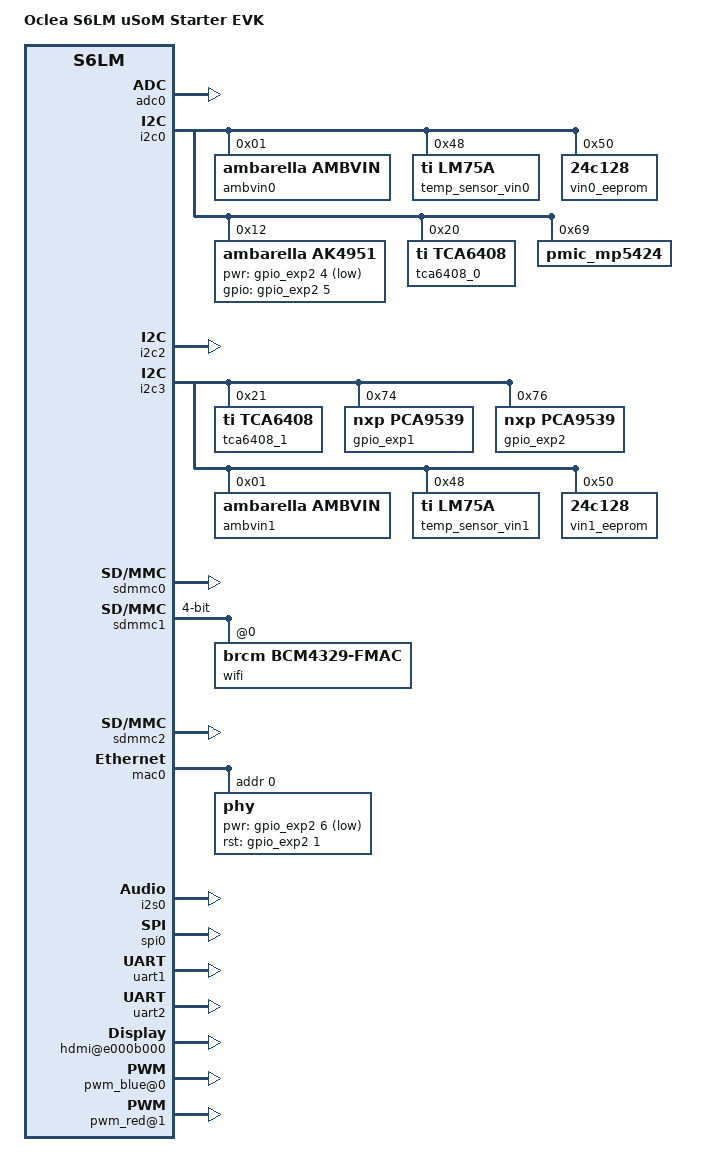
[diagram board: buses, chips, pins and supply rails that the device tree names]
/dts-v1/;
/include/ "ambarella-s6lm.dtsi"
/ {
 reserved-memory {
  #address-cells = <1>;
  #size-cells = <1>;
  ranges;
  linux,cma {
   compatible = "shared-dma-pool";
   reusable;
   size = <0x02000000>;
   linux,cma-default;
  };
  iav_reserved: iav@0x1a800000 {
   compatible = "shared-dma-pool";
   reusable;
   reg = <0x1a800000 (0x40000000 - 0x1a800000 - 0x400000)>;
  };
 };
 iav {
  ambcma {
   compatible = "ambarella,cma";
   memory-region = <&iav_reserved>;
  };
 };
};
/ {
 iav {
  hwtimer {
   compatible = "ambarella,hwtimer";
   interrupts = <0 25 0x1>;
   interrupt-names = "hwtimer";
  };
 };
 clocks {
  pll_out_hdmi: pll_out_hdmi {
   assigned-clock-rates = <270000000>;
  };
  gclk_so: gclk-so {
   assigned-clock-rates = <37125000>;
  };
 };
};
/ {
 som_type = "Oclea S6LM uSoM";
 model = "Oclea S6LM uSoM Starter EVK";
 compatible = "ambarella,s6lm_oclea", "ambarella,s6lm";
 oclea-vin-version = <1>;
 chosen {
  bootargs = "console=ttyS0 noinitrd root=##ROOT_DEVICE## rw rootfstype=ext4 rootwait init=/sbin/init";
 };
 n_apb@e4000000 {
  ntc0: ntc0 {
   compatible = "joinset,ecth100505103f3435f";
   pullup-uv = <1800000>;
   pullup-ohm = <10000>;
   pulldown-ohm = <0>;
   io-channels = <&adc0 0>;
   alias-name = "main-ntc";
   #thermal-sensor-cells = <0>;
  };
  hwid {
   compatible = "oclea,s6lm_uSOM";
   pullup-mv = <1800>;
   io-channels = <&adc0 1>;
   alias-name = "hwid";
  };
  adc0: adc@e4003000 {
   status = "ok";
   amb,channels-used = <0x06>;
   #io-channel-cells = <1>;
  };
  i2c0: i2c@e4008000 {
   status = "ok";
   ambvin0@01 {
    compatible = "ambarella,ambvin";
    reg = <0x01>;
   };
   temp_sensor_vin0: temp_sensor_vin0@48 {
    compatible = "ti,lm75a";
    reg = <0x48>;
    dev-name = "iio:temp_sensor_vin0";
   };
   vin0_eeprom: eeprom@50 {
    compatible = "24c128";
    reg = <0x50>;
    pagesize = <64>;
   };
   ak4951: codec@12 {
    compatible = "ambarella,ak4951";
    #sound-dai-cells = <0>;
    reg = <0x12>;
    pwr-gpios = <&gpio_exp2 4 0x1>;
    gpios = <&gpio_exp2 5 0x0>;
    amb,dmic;
   };
   tca6408_0: tca6408@20 {
    compatible = "ti,tca6408";
    reg = <0x20>;
    gpio-controller;
    #gpio-cells = <2>;
   };
   pmic_mp5424: pmic_mp5424@69 {
    compatible = "pmic_mp5424";
    reg = <0x69>;
   };
  };
  i2c1: i2c@e4009000 {
   status = "disabled";
  };
  i2c2: i2c@e400a000 {
   status = "ok";
  };
  i2c3: i2c@e400b000 {
   status = "ok";
   tca6408_1: tca6408@21 {
    compatible = "ti,tca6408";
    reg = <0x21>;
    gpio-controller;
    #gpio-cells = <2>;
   };
   gpio_exp1: pca9539@74 {
    compatible = "nxp,pca9539";
    reg = <0x74>;
    gpio-controller;
    #gpio-cells = <2>;
   };
    gpio_exp2: pca9539@76 {
    compatible = "nxp,pca9539";
    reg = <0x76>;
    gpio-controller;
    #gpio-cells = <2>;
   };
   ambvin1@01 {
    compatible = "ambarella,ambvin";
    reg = <0x01>;
   };
   temp_sensor_vin1: temp_sensor_vin1@48 {
    compatible = "ti,lm75a";
    reg = <0x48>;
    dev-name = "iio:temp_sensor_vin1";
   };
   vin1_eeprom: eeprom@50 {
    compatible = "24c128";
    reg = <0x50>;
    pagesize = <64>;
   };
  };
 };
 n_ahb@e0000000 {
  sdmmc0: sdmmc0@e0004000 {
   pinctrl-0 = <&sdmmc0_pins_8bit &sdmmc0_reset_pin>;
   amb,fixed-cd = <1>;
   amb,fixed-wp = <0>;
   amb,sd-force-1_8v;
   status = "ok";
  };
  sdmmc1: sdmmc1@e0005000 {
   status = "ok";
   pinctrl-0 = <&sdmmc1_pins_4bit>;
   bus-width = <4>;
   amb,fixed-cd = <1>;
   amb,fixed-wp = <0>;
   amb,sd-force-1_8v;
   amb,sdio-v3-lv-enable;
   wifi@0 {
    compatible = "brcm,bcm4329-fmac";
    reg = <0>;
   };
  };
  sdmmc2: sdmmc2@e0016000 {
   status = "ok";
   pinctrl-0 = <&sdmmc2_pins_4bit &sdmmc2_cd_pin>;
   pwr-gpios = <&gpio_exp2 0 0x1>;
   amb,fixed-wp = <0>;
   no-1-8-v;
  };
  mac0: ethernet@e000e000 {
   amb,tx-clk-invert;
   pinctrl-0 = <&rgmii_pins &enet_2nd_ref_clk_pins_c>;
   phy@0 {
    reg = <0>;
    pwr-gpios = <&gpio_exp2 6 1>;
    rst-gpios = <&gpio_exp2 1 0>;
   };
  };
  i2s0: i2s@e001d000 {
   status = "ok";
  };
  spi0: spi@e0011000 {
   status = "ok";
   cs-gpios = <&gpio 4 0>, <&gpio 5 0>;
  };
  spi1: spi@e0012000 {
   status = "disabled";
  };
  uart1: uart@e0017000 {
   status = "ok";
  };
  uart2: uart@e0018000 {
   pinctrl-0 = <&uart2_pins>;
   status = "ok";
  };
  hdmi@e000b000 {
   status = "ok";
   amb,i2c-adapter = <2>;
  };
 };
 s_ahb@e8000000 {
  rtc@e8001000 {
   status = "ok";
  };
  rng@e8001000 {
   status = "disabled";
  };
 };
 rct@ed080000 {
  usbphy: usbphy@ed080050 {
   amb,ocp-polarity = <0>;
   pinctrl-names;
   pinctrl-0;
   md-gpios = <&tca6408_1 2 0x1>;
   hub-gpios = <&gpio_exp2 11 0x0>;
  };
 };
 bogus_bus {
  wdt_tps3431@0 {
   compatible = "wdt_tps3431";
   en-gpio = <&gpio 36 0>;
   trigger-gpio = <&gpio 7 0>;
   trigger-interval = <40>;
  };
  ircut@4 {
   compatible = "ap1551a";
   reg = <4>;
   sw1-gpio = <&tca6408_0 3 0>;
   sw2-gpio = <&tca6408_0 2 1>;
   dev-name = "iio:ir_cut_vin0";
  };
  ircut@5 {
   compatible = "ap1551a";
   reg = <5>;
   sw1-gpio = <&tca6408_0 7 0>;
   sw2-gpio = <&tca6408_0 6 1>;
   dev-name = "iio:ir_cut_vin1";
  };
  pwm_blue@0 {
   compatible = "pwm-backlight";
   reg = <0>;
   pwms = <&pwm0 0 40000 0>;
   pinctrl-names = "default";
   pinctrl-0 = <&pwm0_pins_a>;
   brightness-levels =
    <0 1 2 3 4 5 6 7 8 9 10 11 12 13 14 15
    16 17 18 19 20 21 22 23 24 25 26 27 28 29 30 31
    32 33 34 35 36 37 38 39 40 41 42 43 44 45 46 47
    48 49 50 51 52 53 54 55 56 57 58 59 60 61 62 63
    64 65 66 67 68 69 70 71 72 73 74 75 76 77 78 79
    80 81 82 83 84 85 86 87 88 89 90 91 92 93 94 95
    96 97 98 99 100 101 102 103 104 105 106 107 108 109 110 111
    112 113 114 115 116 117 118 119 120 121 122 123 124 125 126 127
    128 129 130 131 132 133 134 135 136 137 138 139 140 141 142 143
    144 145 146 147 148 149 150 151 152 153 154 155 156 157 158 159
    160 161 162 163 164 165 166 167 168 169 170 171 172 173 174 175
    176 177 178 179 180 181 182 183 184 185 186 187 188 189 190 191
    192 193 194 195 196 197 198 199 200 201 202 203 204 205 206 207
    208 209 210 211 212 213 214 215 216 217 218 219 220 221 222 223
    224 225 226 227 228 229 230 231 232 233 234 235 236 237 238 239
    240 241 242 243 244 245 246 247 248 249 250 251 252 253 254 255>;
   default-brightness-level = <0>;
  };
  pwm_red@1 {
   compatible = "pwm-backlight";
   reg = <1>;
   pwms = <&pwm0 1 40000 0>;
   pinctrl-names = "default";
   pinctrl-0 = <&pwm1_pins>;
   brightness-levels =
    <0 1 2 3 4 5 6 7 8 9 10 11 12 13 14 15
    16 17 18 19 20 21 22 23 24 25 26 27 28 29 30 31
    32 33 34 35 36 37 38 39 40 41 42 43 44 45 46 47
    48 49 50 51 52 53 54 55 56 57 58 59 60 61 62 63
    64 65 66 67 68 69 70 71 72 73 74 75 76 77 78 79
    80 81 82 83 84 85 86 87 88 89 90 91 92 93 94 95
    96 97 98 99 100 101 102 103 104 105 106 107 108 109 110 111
    112 113 114 115 116 117 118 119 120 121 122 123 124 125 126 127
    128 129 130 131 132 133 134 135 136 137 138 139 140 141 142 143
    144 145 146 147 148 149 150 151 152 153 154 155 156 157 158 159
    160 161 162 163 164 165 166 167 168 169 170 171 172 173 174 175
    176 177 178 179 180 181 182 183 184 185 186 187 188 189 190 191
    192 193 194 195 196 197 198 199 200 201 202 203 204 205 206 207
    208 209 210 211 212 213 214 215 216 217 218 219 220 221 222 223
    224 225 226 227 228 229 230 231 232 233 234 235 236 237 238 239
    240 241 242 243 244 245 246 247 248 249 250 251 252 253 254 255>;
   default-brightness-level = <0>;
  };
  ir_led@2 {
   compatible = "pwm-backlight";
   reg = <20>;
   pwms = <&pwm0 2 40000 0>;
   pinctrl-names = "default";
   pinctrl-0 = <&pwm2_pins>;
   brightness-levels =
    <0 1 2 3 4 5 6 7 8 9 10 11 12 13 14 15
    16 17 18 19 20 21 22 23 24 25 26 27 28 29 30 31
    32 33 34 35 36 37 38 39 40 41 42 43 44 45 46 47
    48 49 50 51 52 53 54 55 56 57 58 59 60 61 62 63
    64 65 66 67 68 69 70 71 72 73 74 75 76 77 78 79
    80 81 82 83 84 85 86 87 88 89 90 91 92 93 94 95
    96 97 98 99 100 101 102 103 104 105 106 107 108 109 110 111
    112 113 114 115 116 117 118 119 120 121 122 123 124 125 126 127
    128 129 130 131 132 133 134 135 136 137 138 139 140 141 142 143
    144 145 146 147 148 149 150 151 152 153 154 155 156 157 158 159
    160 161 162 163 164 165 166 167 168 169 170 171 172 173 174 175
    176 177 178 179 180 181 182 183 184 185 186 187 188 189 190 191
    192 193 194 195 196 197 198 199 200 201 202 203 204 205 206 207
    208 209 210 211 212 213 214 215 216 217 218 219 220 221 222 223
    224 225 226 227 228 229 230 231 232 233 234 235 236 237 238 239
    240 241 242 243 244 245 246 247 248 249 250 251 252 253 254 255>;
   default-brightness-level = <0>;
  };
 };
 iav {
  vinc0 {
    vinrst-gpios = <&gpio 66 0>;
    vinpwr-gpios = <&tca6408_0 0 1>;
  };
  vinc1 {
    vinrst-gpios = <&tca6408_0 5 0>;
   vinpwr-gpios = <&tca6408_0 4 1>;
  };
  voutc0 {
   pinctrl-names;
   pinctrl-0;
  };
 };
 sound {
  compatible = "ambarella,audio-board";
  simple-audio-card,name = "ak4951 @ HAL";
  simple-audio-card,mclk-fs = <256>;
  simple-audio-card,widgets =
         "Speaker", "Speaker",
         "Microphone", "Mic Internal";
  simple-audio-card,routing =
   "DMICLIN", "Mic Internal",
   "DMICRIN", "Mic Internal",
   "DMICL", "DMICLIN",
   "DMICR", "DMICRIN",
   "MIC MUX", "DMICL",
   "MIC MUX", "DMICR",
    "PFSDO MUX", "MIC MUX",
    "SDTO", "PFSDO MUX",
   "PFDAC MUX", "SDTI",
   "DAC", "PFDAC MUX",
   "SPKLO Mixer", "DAC",
   "SPK Amp", "SPKLO Mixer",
   "SPKLO MUX", "SPK Amp",
   "SPKLO", "SPKLO MUX",
   "Speaker", "SPKLO";
  simple-audio-card,dai-link@0 {
   format = "i2s";
   cpu {
     sound-dai = <&i2s0>;
   };
   codec {
    sound-dai = <&ak4951>;
   };
  };
 };
 thermal-zones {
  soc_thermal: soc-thermal {
   polling-delay-passive = <250>;
   polling-delay = <1000>;
   thermal-sensors = <&ntc0>;
   trips {
    soc_alert: soc-alert {
     temperature = <80000>;
     hysteresis = <1000>;
     type = "passive";
    };
    soc_crit: soc-crit {
     temperature = <85000>;
     hysteresis = <1000>;
     type = "critical";
    };
   };
  };
 };
};
